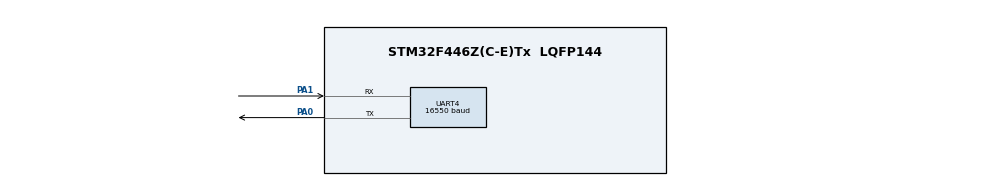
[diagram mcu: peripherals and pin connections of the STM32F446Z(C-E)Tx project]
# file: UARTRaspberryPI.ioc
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Mcu.Family=STM32F4
Mcu.Name=STM32F446Z(C-E)Tx
Mcu.Package=LQFP144
NVIC.PriorityGroup=NVIC_PRIORITYGROUP_4
PA0-WKUP.Mode=Asynchronous
PA0-WKUP.Signal=UART4_TX
PA1.Mode=Asynchronous
PA1.Signal=UART4_RX
ProjectManager.HeapSize=0x200
ProjectManager.StackSize=0x400
ProjectManager.TargetToolchain=STM32CubeIDE
RCC.CortexFreq_Value=16000000
RCC.USBFreq_Value=96000000
RCC.VCOOutputFreq_Value=192000000
UART4.BaudRate=16550
UART4.VirtualMode=Asynchronous
board=custom

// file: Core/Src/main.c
/* USER CODE BEGIN Header */
/**
  ******************************************************************************
  * @file           : main.c
  * @brief          : Main program body
  ******************************************************************************
  * @attention
  *
  * Copyright (c) 2023 STMicroelectronics.
  * All rights reserved.
  *
  * This software is licensed under terms that can be found in the LICENSE file
  * in the root directory of this software component.
  * If no LICENSE file comes with this software, it is provided AS-IS.
  *
  ******************************************************************************
  */
/* USER CODE END Header */
#include "main.h"

UART_HandleTypeDef huart4;

void SystemClock_Config(void);
static void MX_GPIO_Init(void);
static void MX_UART4_Init(void);

int main(void)
{

  /* MCU Configuration--------------------------------------------------------*/

  /* Reset of all peripherals, Initializes the Flash interface and the Systick. */
  HAL_Init();

  /* Configure the system clock */
  SystemClock_Config();

  /* Initialize all configured peripherals */
  MX_GPIO_Init();
  MX_UART4_Init();

  /* Infinite loop */
  /* USER CODE BEGIN WHILE */

  while (1)
  {
	  uint8_t Rx_data[2];
	  HAL_UART_Receive (&huart4, Rx_data, 8, 100);
	  HAL_Delay(1000);
	  //uint8_t msg[] = "WE ARE COMPLETE\n";
	  int s = (sizeof(Rx_data));
	  for (int i=1; i < s;++i ) HAL_UART_Transmit(&huart4,Rx_data,sizeof(Rx_data[i]),HAL_MAX_DELAY);
	  // msg[1] = \n';'a'
	  //msg[2] = '\0';
	  //HAL_UART_Transmit(&huart4,(uint8_t *)msg,sizeof(msg),HAL_MAX_DELAY);
	  HAL_Delay(1000);
	  //uint8_t Rx_data[10];
	  //HAL_UART_Receive (&huart4, Rx_data, 4, 100);
	  //HAL_Delay(1000);

    /* USER CODE END WHILE */

  }
}

void SystemClock_Config(void)
{
  RCC_OscInitTypeDef RCC_OscInitStruct = {0};
  RCC_ClkInitTypeDef RCC_ClkInitStruct = {0};

  /** Configure the main internal regulator output voltage
  */
  __HAL_RCC_PWR_CLK_ENABLE();
  __HAL_PWR_VOLTAGESCALING_CONFIG(PWR_REGULATOR_VOLTAGE_SCALE3);

  /** Initializes the RCC Oscillators according to the specified parameters
  * in the RCC_OscInitTypeDef structure.
  */
  RCC_OscInitStruct.OscillatorType = RCC_OSCILLATORTYPE_HSI;
  RCC_OscInitStruct.HSIState = RCC_HSI_ON;
  RCC_OscInitStruct.HSICalibrationValue = RCC_HSICALIBRATION_DEFAULT;
  RCC_OscInitStruct.PLL.PLLState = RCC_PLL_NONE;
  if (HAL_RCC_OscConfig(&RCC_OscInitStruct) != HAL_OK)
  {
    Error_Handler();
  }

  /** Initializes the CPU, AHB and APB buses clocks
  */
  RCC_ClkInitStruct.ClockType = RCC_CLOCKTYPE_HCLK|RCC_CLOCKTYPE_SYSCLK
                              |RCC_CLOCKTYPE_PCLK1|RCC_CLOCKTYPE_PCLK2;
  RCC_ClkInitStruct.SYSCLKSource = RCC_SYSCLKSOURCE_HSI;
  RCC_ClkInitStruct.AHBCLKDivider = RCC_SYSCLK_DIV1;
  RCC_ClkInitStruct.APB1CLKDivider = RCC_HCLK_DIV1;
  RCC_ClkInitStruct.APB2CLKDivider = RCC_HCLK_DIV1;

  if (HAL_RCC_ClockConfig(&RCC_ClkInitStruct, FLASH_LATENCY_0) != HAL_OK)
  {
    Error_Handler();
  }
}

static void MX_UART4_Init(void)
{

  huart4.Instance = UART4;
  huart4.Init.BaudRate = 9600;
  huart4.Init.WordLength = UART_WORDLENGTH_8B;
  huart4.Init.StopBits = UART_STOPBITS_1;
  huart4.Init.Parity = UART_PARITY_NONE;
  huart4.Init.Mode = UART_MODE_TX_RX;
  huart4.Init.HwFlowCtl = UART_HWCONTROL_NONE;
  huart4.Init.OverSampling = UART_OVERSAMPLING_16;
  if (HAL_UART_Init(&huart4) != HAL_OK)
  {
    Error_Handler();
  }

}

static void MX_GPIO_Init(void)
{

  /* GPIO Ports Clock Enable */
  __HAL_RCC_GPIOA_CLK_ENABLE();

}

void Error_Handler(void)
{
  __disable_irq();
  while (1)
  {
  }
}
